# PIC32CX5109BZ31032 device description
Architecture: CORTEX-M4; Family: PIC32CX; Series: PIC32CXBZ31
Registers are 32-bit, read-write, reset 0x0 unless marked. A register's access mark holds for its fields unless they carry their own. Offsets are from the block's base; [hi:lo] are bit positions; {n}, {i} and the like mark numbered series.

## WDT — Watch Dog Timer
Instances: WDT 0x44000500
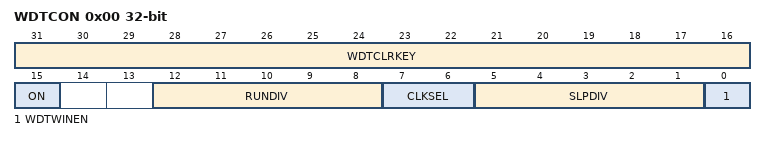
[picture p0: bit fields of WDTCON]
0x00 WDTCON reset not defined — Watchdog Timer Control Register
  [31:16] WDTCLRKEY
  [15] ON — Watchdog Timer Enable bit
    1=WDTEN (The WDT module is enabled); 0=WDTOFF (The WDT module is disabled)
  [12:8] RUNDIV
  [7:6] CLKSEL
  [5:1] SLPDIV
  [0] WDTWINEN — Watchdog Timer Window Enable bit
    1=WDTWINEN (Enable windowed Watchdog Timer); 0=WDTWINDIS (Disable windowed Watchdog Timer)
0x04 WDTCONCLR
0x08 WDTCONSET
0x0C WDTCONINV

## ARB — Radio Arbiter
Instances: ARB 0x41011000
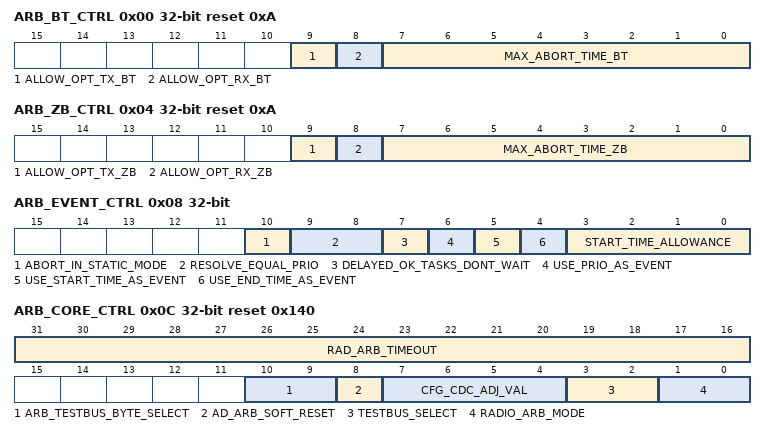
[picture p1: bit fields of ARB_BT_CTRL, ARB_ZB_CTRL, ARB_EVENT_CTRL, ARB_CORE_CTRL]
0x00 ARB_BT_CTRL reset 0xA
  [9] ALLOW_OPT_TX_BT — BT allow optimistic tx
  [8] ALLOW_OPT_RX_BT — BT allow optimistic rx
  [7:0] MAX_ABORT_TIME_BT — BT max abort time
0x04 ARB_ZB_CTRL reset 0xA
  [9] ALLOW_OPT_TX_ZB — ZB allow optimistic tx
  [8] ALLOW_OPT_RX_ZB — ZB allow optimistic rx
  [7:0] MAX_ABORT_TIME_ZB — ZB max abort time
0x08 ARB_EVENT_CTRL
  [10] ABORT_IN_STATIC_MODE
  [9:8] RESOLVE_EQUAL_PRIO
  [7] DELAYED_OK_TASKS_DONT_WAIT
  [6] USE_PRIO_AS_EVENT
  [5] USE_START_TIME_AS_EVENT
  [4] USE_END_TIME_AS_EVENT
  [3:0] START_TIME_ALLOWANCE — minimum change needed in the start time to be considered as an arbitration event.
0x0C ARB_CORE_CTRL reset 0x140
  [31:16] RAD_ARB_TIMEOUT, [10:9] ARB_TESTBUS_BYTE_SELECT, [8] AD_ARB_SOFT_RESET, [7:4] CFG_CDC_ADJ_VAL, [3:2] TESTBUS_SELECT, [1:0] RADIO_ARB_MODE
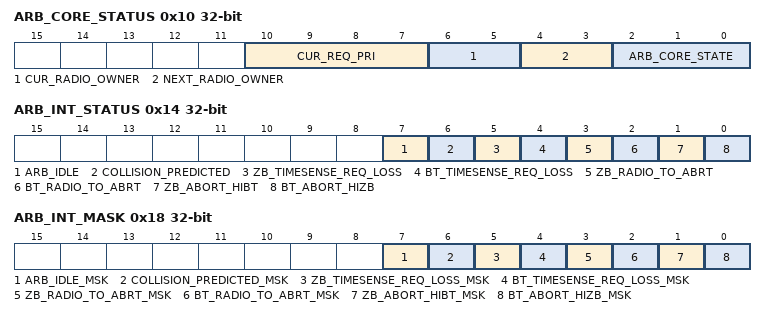
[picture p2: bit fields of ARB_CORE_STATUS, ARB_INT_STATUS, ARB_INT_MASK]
0x10 ARB_CORE_STATUS ro
  [10:7] CUR_REQ_PRI, [6:5] CUR_RADIO_OWNER, [4:3] NEXT_RADIO_OWNER, [2:0] ARB_CORE_STATE
0x14 ARB_INT_STATUS ro
  [7] ARB_IDLE, [6] COLLISION_PREDICTED, [5] ZB_TIMESENSE_REQ_LOSS, [4] BT_TIMESENSE_REQ_LOSS, [3] ZB_RADIO_TO_ABRT, [2] BT_RADIO_TO_ABRT, [1] ZB_ABORT_HIBT, [0] BT_ABORT_HIZB
0x18 ARB_INT_MASK
  [7] ARB_IDLE_MSK, [6] COLLISION_PREDICTED_MSK, [5] ZB_TIMESENSE_REQ_LOSS_MSK, [4] BT_TIMESENSE_REQ_LOSS_MSK, [3] ZB_RADIO_TO_ABRT_MSK, [2] BT_RADIO_TO_ABRT_MSK, [1] ZB_ABORT_HIBT_MSK, [0] BT_ABORT_HIZB_MSK

## BTZBSYS — BT ZB Subsystem
Instances: BTZBSYS 0x41014000
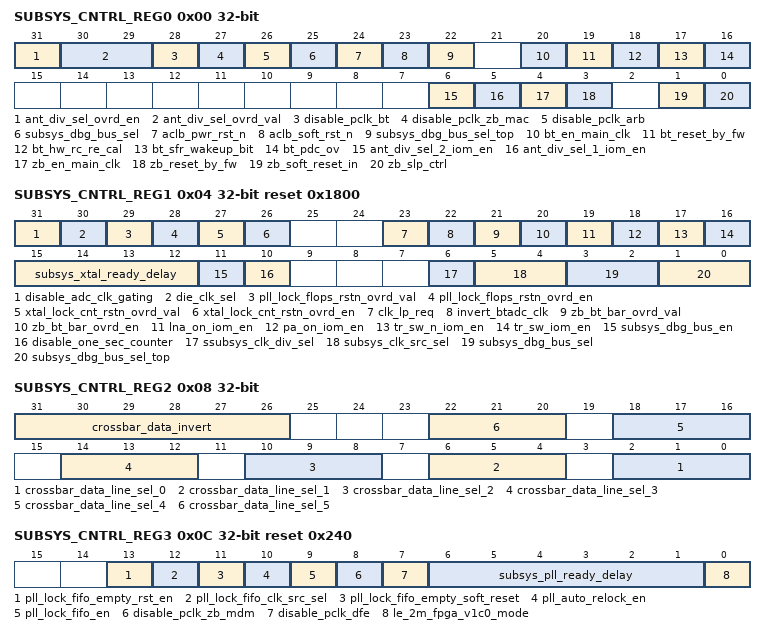
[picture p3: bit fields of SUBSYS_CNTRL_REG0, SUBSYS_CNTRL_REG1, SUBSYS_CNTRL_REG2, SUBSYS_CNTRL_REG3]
0x00 SUBSYS_CNTRL_REG0
  [31] ant_div_sel_ovrd_en, [30:29] ant_div_sel_ovrd_val, [28] disable_pclk_bt, [27] disable_pclk_zb_mac, [26] disable_pclk_arb, [25] subsys_dbg_bus_sel, [24] aclb_pwr_rst_n, [23] aclb_soft_rst_n, [22] subsys_dbg_bus_sel_top, [20] bt_en_main_clk, [19] bt_reset_by_fw, [18] bt_hw_rc_re_cal, [17] bt_sfr_wakeup_bit, [16] bt_pdc_ov, [6] ant_div_sel_2_iom_en, [5] ant_div_sel_1_iom_en, [4] zb_en_main_clk, [3] zb_reset_by_fw, [1] zb_soft_reset_in, [0] zb_slp_ctrl
0x04 SUBSYS_CNTRL_REG1 reset 0x1800
  [31] disable_adc_clk_gating
  [30] die_clk_sel
  [29] pll_lock_flops_rstn_ovrd_val
  [28] pll_lock_flops_rstn_ovrd_en
  [27] xtal_lock_cnt_rstn_ovrd_val
  [26] xtal_lock_cnt_rstn_ovrd_en
  [23] clk_lp_req
  [22] invert_btadc_clk
  [21] zb_bt_bar_ovrd_val
  [20] zb_bt_bar_ovrd_en
  [19] lna_on_iom_en
  [18] pa_on_iom_en
  [17] tr_sw_n_iom_en
  [16] tr_sw_iom_en
  [15:12] subsys_xtal_ready_delay
  [11] subsys_dbg_bus_en
  [10] disable_one_sec_counter
  [6] ssubsys_clk_div_sel — subsys_clk_div_sel
  [5:4] subsys_clk_src_sel
  [3:2] subsys_dbg_bus_sel
  [1:0] subsys_dbg_bus_sel_top
0x08 SUBSYS_CNTRL_REG2
  [31:26] crossbar_data_invert, [4n+2:4n] crossbar_data_line_sel_{n} (n=0..5)
0x0C SUBSYS_CNTRL_REG3 reset 0x240
  [13] pll_lock_fifo_empty_rst_en, [12] pll_lock_fifo_clk_src_sel, [11] pll_lock_fifo_empty_soft_reset, [10] pll_auto_relock_en, [9] pll_lock_fifo_en, [8] disable_pclk_zb_mdm, [7] disable_pclk_dfe, [6:1] subsys_pll_ready_delay, [0] le_2m_fpga_v1c0_mode
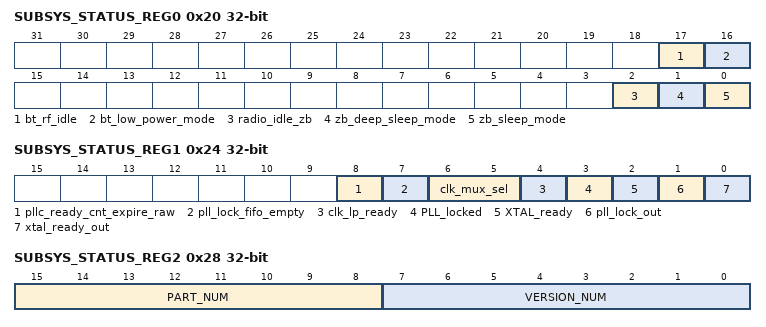
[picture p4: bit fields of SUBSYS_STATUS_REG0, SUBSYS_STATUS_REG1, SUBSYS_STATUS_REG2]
0x20 SUBSYS_STATUS_REG0 ro
  [17] bt_rf_idle, [16] bt_low_power_mode, [2] radio_idle_zb, [1] zb_deep_sleep_mode, [0] zb_sleep_mode
0x24 SUBSYS_STATUS_REG1 ro
  [8] pllc_ready_cnt_expire_raw
  [7] pll_lock_fifo_empty — XTAL_ready
  [6:5] clk_mux_sel — clk_mux_sel0
  [4] clk_lp_ready
  [3] PLL_locked
  [2] XTAL_ready
  [1] pll_lock_out
  [0] xtal_ready_out
0x28 SUBSYS_STATUS_REG2 ro
  [15:8] PART_NUM, [7:0] VERSION_NUM
